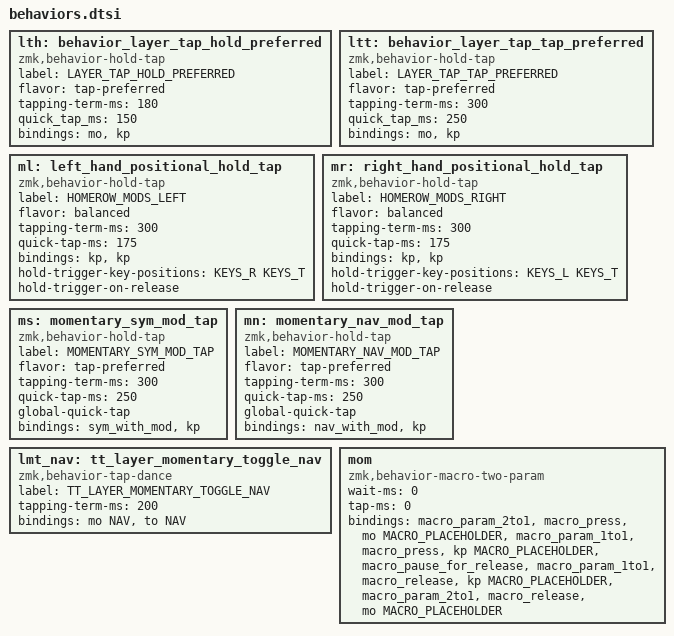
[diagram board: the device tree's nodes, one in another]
// layer tap - hold preferred
lth: behavior_layer_tap_hold_preferred {
	compatible = "zmk,behavior-hold-tap";
	label = "LAYER_TAP_HOLD_PREFERRED";
	#binding-cells = <2>;
	flavor = "tap-preferred";
	tapping-term-ms = <180>;
	quick_tap_ms = <150>;
	bindings = <&mo>, <&kp>;
};

// layer tap - tap preferred
ltt: behavior_layer_tap_tap_preferred {
	compatible = "zmk,behavior-hold-tap";
	label = "LAYER_TAP_TAP_PREFERRED";
	#binding-cells = <2>;
	flavor = "tap-preferred";
	tapping-term-ms = <300>;
	quick_tap_ms = <250>;
	bindings = <&mo>, <&kp>;
};


/**
 * Positional hold-tap behaviors for homerow mods
 *
 * Urob's timeless HRM https://github.com/urob/zmk-config
 */
ml: left_hand_positional_hold_tap {
	compatible = "zmk,behavior-hold-tap";
	label = "HOMEROW_MODS_LEFT";
	#binding-cells = <2>;
	//global-quick-tap;
	flavor = "balanced";
	tapping-term-ms = <300>;
	quick-tap-ms = <175>; // repeat on tap-into-hold
	bindings = <&kp>, <&kp>;
	hold-trigger-key-positions = <KEYS_R KEYS_T>;
	hold-trigger-on-release; // delay positional check until key-release
};
mr: right_hand_positional_hold_tap {
	compatible = "zmk,behavior-hold-tap";
	label = "HOMEROW_MODS_RIGHT";
	#binding-cells = <2>;
	//global-quick-tap;
	flavor = "balanced";
	tapping-term-ms = <300>;
	quick-tap-ms = <175>; // repeat on tap-into-hold
	bindings = <&kp>, <&kp>;
	hold-trigger-key-positions = <KEYS_L KEYS_T>;
	hold-trigger-on-release; // delay positional check until key-release
};


/**
 * Layers with mods
 */
ms: momentary_sym_mod_tap {
	compatible = "zmk,behavior-hold-tap";
	label = "MOMENTARY_SYM_MOD_TAP";
	#binding-cells = <2>;
	flavor = "tap-preferred";
	tapping-term-ms = <300>;
	quick-tap-ms = <250>;
	global-quick-tap;
	bindings = <&sym_with_mod>, <&kp>;
};

mn: momentary_nav_mod_tap {
	compatible = "zmk,behavior-hold-tap";
	label = "MOMENTARY_NAV_MOD_TAP";
	#binding-cells = <2>;
	flavor = "tap-preferred";
	tapping-term-ms = <300>;
	quick-tap-ms = <250>;
	global-quick-tap;
	bindings = <&nav_with_mod>, <&kp>;
};


/**
 * Tap dances
 */

//lmt_nav_kpd: tt_layer_momentary_toggle_nav_kpd {
//	compatible = "zmk,behavior-tap-dance";
//	label = "TT_LAYER_MOMENTARY_TOGGLE_NAV_KPD";
//	#binding-cells = <0>;
//	tapping-term-ms = <200>;
//	bindings = <&mo NAV>, <&mo KPD>;
//};

lmt_nav: tt_layer_momentary_toggle_nav {
	compatible = "zmk,behavior-tap-dance";
	label = "TT_LAYER_MOMENTARY_TOGGLE_NAV";
	#binding-cells = <0>;
	tapping-term-ms = <200>;
	bindings = <&mo NAV>, <&to NAV>;
};

//lmt_kcd: tt_layer_momentary_toggle_kcd {
//	compatible = "zmk,behavior-tap-dance";
//	label = "TT_LAYER_MOMENTARY_TOGGLE_KCD";
//	#binding-cells = <0>;
//	tapping-term-ms = <200>;
//	bindings = <&mo KCD>, <&to KCD>;
//};

//td_comma_commaspace: tap_dance_comma_commaspace {
//	compatible = "zmk,behaviour-tap-dance";
//	label = "TAP_DANCE_COMMA_COMMASPACE";
//	#binding-cells = <0>;
//	tapping-term-ms = <200>;
//	bingings = <&mo COMMA>, <&comma_spc>;
//};


/**
 * From Urob's space configs:
 * Tap: space | Shift + tap: dot -> space -> sticky shift | Hold: nav layer.
 */
/*
lt_spc: lt_spc {
	compatible = "zmk,behavior-hold-tap";
	#binding-cells = <2>;
	bindings = <&mo>, <&spc_morph>;
	flavor = "balanced";
	tapping-term-ms = <200>;
	quick-tap-ms = <175>;
};
kt_spc: kt_spc {
	compatible = "zmk,behavior-hold-tap";
	#binding-cells = <2>;
	bindings = <&kp>, <&spc_morph>;
	flavor = "balanced";
	tapping-term-ms = <200>;
	quick-tap-ms = <175>;
};
// Morphing space behavior: tap space, shift+tap dot_space macro
spc_morph: spc_morph {
	compatible = "zmk,behavior-mod-morph";
	#binding-cells = <0>;
	mods = <(MOD_LSFT | MOD_RSFT)>;                      \
	bindings = <&kp SPACE>, <&dot_spc>;
};
dot_spc: dot_spc {
	compatible = "zmk,behavior-macro";
	#binding-cells = <0>;
	bindings = <&kp DOT &kp SPACE &sk LSHFT>;
	wait-ms = <0>;
	tap-ms = <5>;
};
*/


/**
 * Temporarily switches to a layer (`&mo`) while a modifier is held.
 * Analogous to QMK's `LM()`, using a parameterized macro.
 *
 * Params:
 *  - Modifier to press while layer is active
 *  - Layer to switch to
 *
 * Example:
 *  `&mom LSFT NUM`
 */
mom: mom {
	compatible = "zmk,behavior-macro-two-param";
	wait-ms = <0>;
	tap-ms = <0>;
	#binding-cells = <2>;
	bindings
		= <&macro_param_2to1>
		, <&macro_press &mo MACRO_PLACEHOLDER>
		, <&macro_param_1to1>
		, <&macro_press &kp MACRO_PLACEHOLDER>
		, <&macro_pause_for_release>
		, <&macro_param_1to1>
		, <&macro_release &kp MACRO_PLACEHOLDER>
		, <&macro_param_2to1>
		, <&macro_release &mo MACRO_PLACEHOLDER>
		;
// 	bindings
// 		= <&macro_param_1to1>
// 		, <&macro_press &mo MACRO_PLACEHOLDER>
// 		, <&macro_param_2to1>
// 		, <&macro_press &kp MACRO_PLACEHOLDER>
// 		, <&macro_pause_for_release>
// 		, <&macro_param_2to1>
// 		, <&macro_release &kp MACRO_PLACEHOLDER>
// 		, <&macro_param_1to1>
// 		, <&macro_release &mo MACRO_PLACEHOLDER>
// 		;
};
